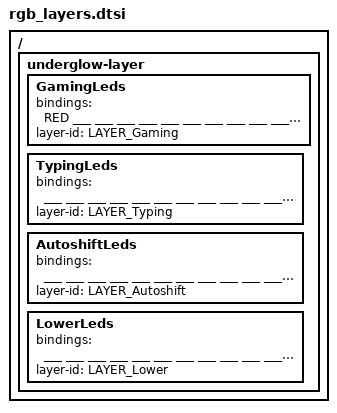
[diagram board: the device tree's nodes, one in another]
// GENERATED by tools/gen_rgb_layers.py from config/glove80.keymap. Do not edit by hand.
// Per-key LEDs for mode layers (requires MoErgo PR36 firmware, CONFIG_EXPERIMENTAL_RGB_LAYER).
// Layers without an entry here keep the LEDs dark.

#define GRN &ug 0x00FF40
#define ORN &ug 0xFF7000
#define CYN &ug 0x00C8FF
#define RED &ug 0xFF0000
#define BLU &ug 0x0030FF
#define MAJ &ug 0xFF00C0
#define AZU &ug 0x2060FF
#define PUR &ug 0x9020FF
#define GOL &ug 0xFFC000
#define ___ &ug 0x000000

/ {
    underglow-layer {
        GamingLeds {
            bindings = <
                RED ___ ___ ___ ___ ___ ___ ___ ___ ___
                ___ ___ ___ ___ ___ ___ ___ ___ ___ ___ ___ ___
                ___ ORN ORN ORN ORN ORN ___ ___ ___ ___ ___ ___
                ORN CYN ORN GRN ORN ORN ___ ___ ___ ___ ___ ___
                ORN CYN GRN GRN GRN MAJ CYN CYN ORN RED ___ BLU ___ ___ ___ ___ ___ ___
                ___ CYN ORN ORN MAJ CYN CYN BLU ___ ___ ___ ___ ___ ___ ___ ___
            >;
            layer-id = <LAYER_Gaming>;
        };
        TypingLeds {
            bindings = <
                ___ ___ ___ ___ ___ ___ ___ ___ ___ ___
                ___ ___ ___ ___ ___ ___ ___ ___ ___ ___ ___ ___
                ___ ___ ___ ___ ___ ___ ___ ___ ___ ___ ___ ___
                ___ AZU AZU AZU AZU ___ ___ AZU AZU AZU AZU ___
                ___ ___ ___ ___ ___ ___ ___ ___ ___ ___ ___ ___ ___ ___ ___ ___ ___ ___
                ___ ___ ___ ___ ___ ___ ___ ___ ___ ___ ___ ___ ___ ___ ___ ___
            >;
            layer-id = <LAYER_Typing>;
        };
        AutoshiftLeds {
            bindings = <
                ___ ___ ___ ___ ___ ___ ___ ___ ___ ___
                ___ ___ ___ ___ ___ ___ ___ ___ ___ ___ ___ ___
                ___ ___ ___ ___ ___ ___ ___ ___ ___ ___ ___ ___
                ___ PUR PUR PUR PUR ___ ___ PUR PUR PUR PUR ___
                ___ ___ ___ ___ ___ ___ ___ ___ ___ ___ ___ ___ ___ ___ ___ ___ ___ ___
                ___ ___ ___ ___ ___ ___ ___ ___ ___ ___ ___ ___ ___ ___ ___ ___
            >;
            layer-id = <LAYER_Autoshift>;
        };
        LowerLeds {
            bindings = <
                ___ ___ ___ ___ ___ ___ ___ ___ ___ ___
                ___ ___ ___ ___ ___ ___ ___ CYN ___ CYN CYN ___
                ___ ___ ___ ___ ___ ___ ___ GOL GOL GOL CYN ___
                ___ ___ ___ ___ ___ ___ ___ GOL GOL GOL CYN ___
                ___ ___ ___ ___ ___ ___ ___ ___ ___ ___ ___ ___ CYN GOL GOL GOL CYN ___
                ___ ___ ___ ___ ___ ___ ___ ___ ___ ___ ___ GOL GOL CYN CYN ___
            >;
            layer-id = <LAYER_Lower>;
        };
    };
};
